# GPIO register map
Vendor: Texas Instruments
Peripheral module from a debugger description file (folder CC27xxx15).
Registers are 32-bit, access per field, reset 0x0 unless marked. A register's access mark holds for its fields unless they carry their own. Offsets are as the file gives them; lines under a group give offsets from that group; [hi:lo] are bit positions; {n}, {i} and the like mark numbered series; 'fields as' and 'values as' point back to an identical list; <NAME> marks a mode.

## GPIO — MCU GPIO - I/F for controlling and reading IO status and IO event status
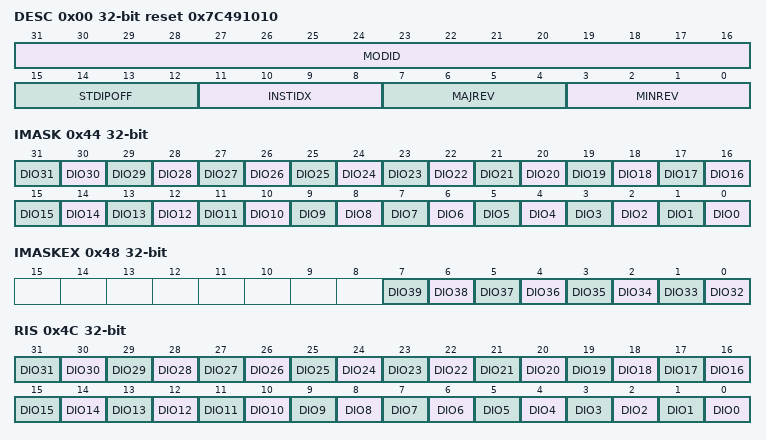
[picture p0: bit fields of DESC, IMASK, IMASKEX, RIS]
0x00 DESC ro reset 0x7C491010 — Description Register. This register provides IP module ID, revision information, instance index and standard MMR registers offset.
  [31:16] MODID — Module identifier used to uniquely identify this IP.
  [15:12] STDIPOFF — Standard IP MMR block offset. Standard IP MMRs are the set from aggregated IRQ registers till DTB. 0: Standard IP MMRs do not exist 0x1-0xF: Standard IP MMRs begin at offset of (64*STDIPOFF from the base IP address)
  [11:8] INSTIDX — IP Instance ID number. If multiple instances of IP exist in the device, this field can identify the instance number (0-15).
  [7:4] MAJREV — Major revision of IP (0-15).
  [3:0] MINREV — Minor revision of IP (0-15).
0x04 DESCEX ro reset 0x27 — Provide IP-specific instance information
  [5:0] NUMDIO — This provides the total number of DIOs supported by GPIO. The number of DIOs supprted is NUMDIO + 1
0x44 IMASK rw — Interrupt mask for DIO pins
  [all] fields
    1=SET (Set Interrrupt Mask); 0=CLR (Clear Interrupt Mask)
  [n] DIO{n} (n=0..31) — Interrupt mask for DIO{n}
0x48 IMASKEX — Interrupt mask for DIO pins
  [all] fields
    1=SET (Set Interrrupt Mask); 0=CLR (Clear Interrupt Mask)
  [n-32] DIO{n} rw (n=32..39) — Interrupt mask for DIO{n}
0x4C RIS ro — Raw interrupt flag for DIO pins
  [all] fields
    1=SET (Interrupt occured); 0=CLR (Interrupt did not occur)
  [n] DIO{n} (n=0..31) — Raw interrupt flag for DIO{n}
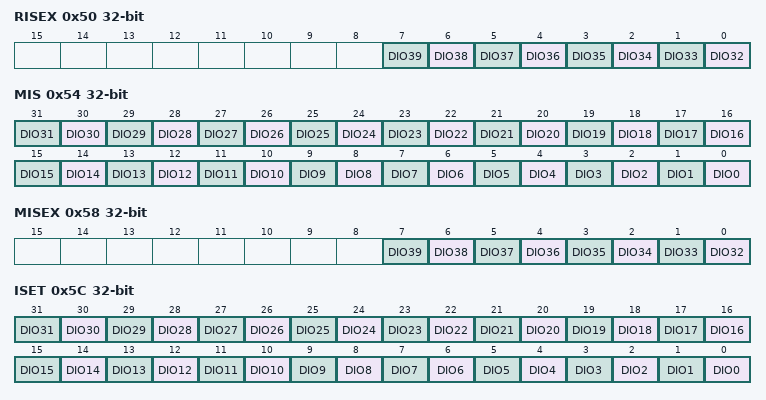
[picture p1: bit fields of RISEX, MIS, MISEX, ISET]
0x50 RISEX ro — Raw interrupt flag for DIO pins
  [all] fields
    1=SET (Interrupt occured); 0=CLR (Interrupt did not occur)
  [n-32] DIO{n} (n=32..39) — Raw interrupt flag for DIO{n}
0x54 MIS ro — Masked interrupt flag for DIO pins
  [all] fields
    1=SET (Interrupt occured); 0=CLR (Interrupt did not occur)
  [n] DIO{n} (n=0..31) — Masked interrupt flag for DIO{n}
0x58 MISEX ro — Masked interrupt flag for DIO pins
  [all] fields
    1=SET (Interrupt occured); 0=CLR (Interrupt did not occur)
  [n-32] DIO{n} (n=32..39) — Masked interrupt flag for DIO{n}
0x5C ISET wo — Set interrupt flag in RIS by writing a one
  [all] fields
    1=SET (Set Interrupt); 0=NOEFF (Writing 0 has no effect)
  [n] DIO{n} (n=0..31) — Set DIO{n} in RIS
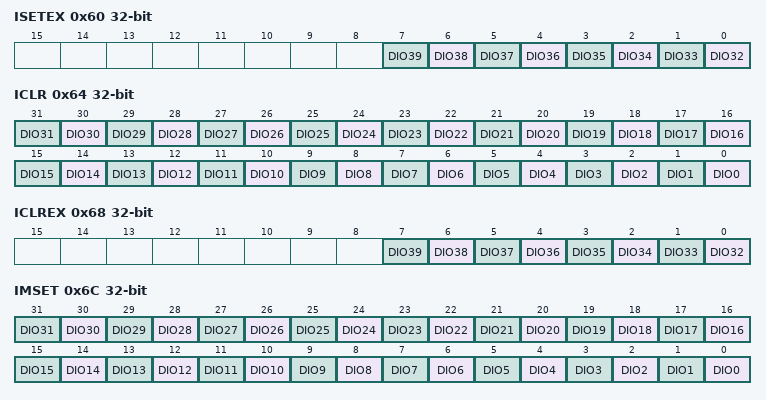
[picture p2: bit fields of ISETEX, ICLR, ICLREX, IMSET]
0x60 ISETEX — Set interrupt flag in RIS by writing a one
  [all] fields
    1=SET (Set Interrupt); 0=NOEFF (Writing 0 has no effect)
  [n-32] DIO{n} wo (n=32..39) — Set DIO{n} in RIS
0x64 ICLR wo — Clear interrupt flag in RIS by writing a one
  [all] fields
    1=CLR (Clear Interrupt); 0=NOEFF (Writing 0 has no effect)
  [n] DIO{n} (n=0..31) — Clears DIO{n} in RIS
0x68 ICLREX — Clear interrupt flag in RIS by writing a one
  [all] fields
    1=CLR (Clear Interrupt); 0=NOEFF (Writing 0 has no effect)
  [n-32] DIO{n} wo (n=32..39) — Clears DIO{n} in RIS
0x6C IMSET wo — Set interrupt mask in IMASK by writing a one
  [all] fields
    1=SET (Set interrupt mask); 0=NOEFF (Writing 0 has no effect)
  [n] DIO{n} (n=0..31) — Sets DIO{n} in IMASK
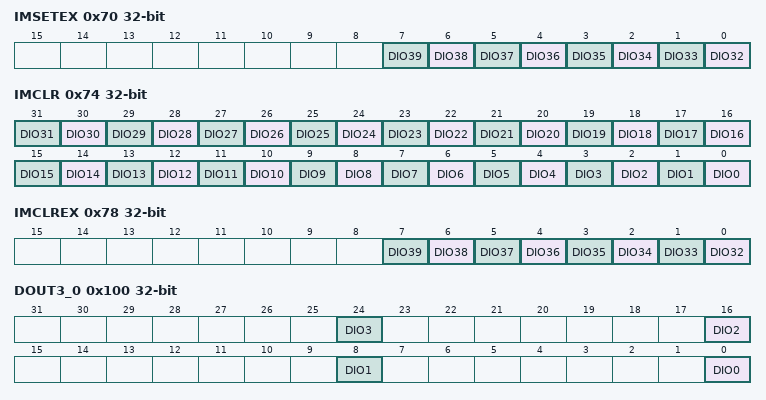
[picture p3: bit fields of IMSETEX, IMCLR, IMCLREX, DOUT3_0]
0x70 IMSETEX — Set interrupt mask in IMASK by writing a one
  [all] fields
    values as the fields of IMSET
  [n-32] DIO{n} wo (n=32..39) — Sets DIO{n} in IMASK
0x74 IMCLR wo — Clear interrupt mask in IMASK by writing a one
  [all] fields
    1=CLR (Clear interrupt mask); 0=NOEFF (Writing 0 has no effect)
  [n] DIO{n} (n=0..31) — Clears DIO{n} in IMASK
0x78 IMCLREX — Clear interrupt mask in IMASK by writing a one
  [all] fields
    values as the fields of IMCLR
  [n-32] DIO{n} wo (n=32..39) — Clears DIO{n} in IMASK
0x100 DOUT3_0 — Alias register for byte access to DOUT31_0[3:0] bits.
  [all] fields
    1=ONE (Output is set to 1); 0=ZERO (Output is set to 0)
  [8n] DIO{n} rw (n=0..3) — Data output for DIO{n}
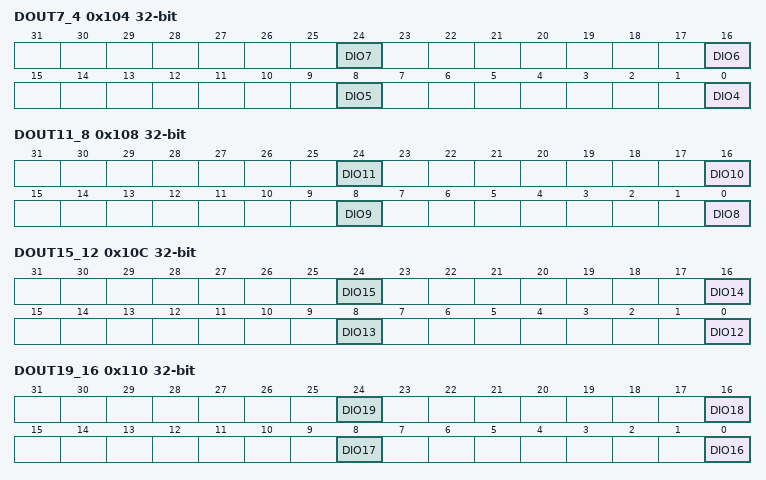
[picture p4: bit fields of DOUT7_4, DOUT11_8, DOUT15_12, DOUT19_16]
0x104 DOUT7_4 — Alias register for byte access to DOUT31_0[7:4] bits
  [all] fields
    1=ONE (Output is set to 1); 0=ZERO (Output is set to 0)
  [8n-32] DIO{n} rw (n=4..7) — Data output for DIO{n}
0x108 DOUT11_8 — Alias register for byte access to DOUT31_0[11:8] bits
  [all] fields
    1=ONE (Output is set to 1); 0=ZERO (Output is set to 0)
  [8n-64] DIO{n} rw (n=8..11) — Data output for DIO{n}
0x10C DOUT15_12 — Alias register for byte access to DOUT31_0[15:12] bits
  [all] fields
    1=ONE (Output is set to 1); 0=ZERO (Output is set to 0)
  [8n-96] DIO{n} rw (n=12..15) — Data output for DIO{n}
0x110 DOUT19_16 — Alias register for byte access to DOUT31_0[19:16] bits
  [all] fields
    1=ONE (Output is set to 1); 0=ZERO (Output is set to 0)
  [8n-128] DIO{n} rw (n=16..19) — Data output for DIO{n}
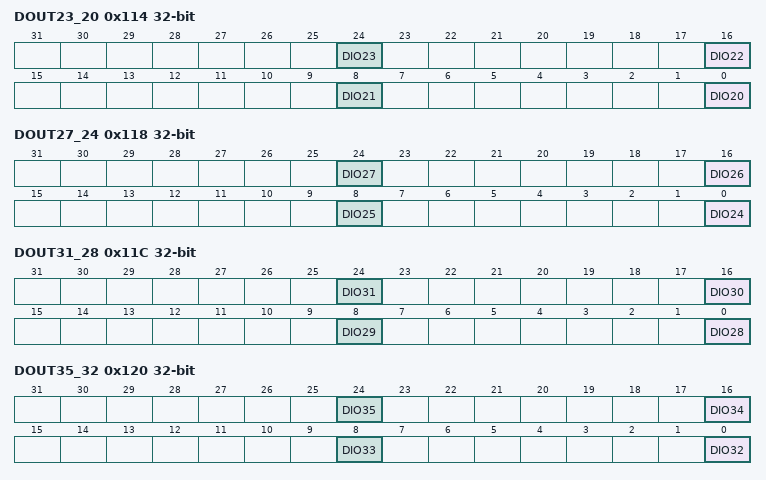
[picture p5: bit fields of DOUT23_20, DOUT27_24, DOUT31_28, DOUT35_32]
0x114 DOUT23_20 — Alias register for byte access to DOUT31_0[23:20] bits
  [all] fields
    1=ONE (Output is set to 1); 0=ZERO (Output is set to 0)
  [8n-160] DIO{n} rw (n=20..23) — Data output for DIO{n}
0x118 DOUT27_24 — Alias register for byte access to DOUT31_0[27:24] bits
  [all] fields
    1=ONE (Output is set to 1); 0=ZERO (Output is set to 0)
  [8n-192] DIO{n} rw (n=24..27) — Data output for DIO{n}
0x11C DOUT31_28 — Alias register for byte access to DOUT31_0[31:28] bits
  [all] fields
    1=ONE (Output is set to 1); 0=ZERO (Output is set to 0)
  [8n-224] DIO{n} rw (n=28..31) — Data output for DIO{n}
0x120 DOUT35_32 — Alias register for byte access to DOUT63_32[35:32] bits
  [all] fields
    1=ONE (Output is set to 1); 0=ZERO (Output is set to 0)
  [8n-256] DIO{n} rw (n=32..35) — Data output for DIO{n}
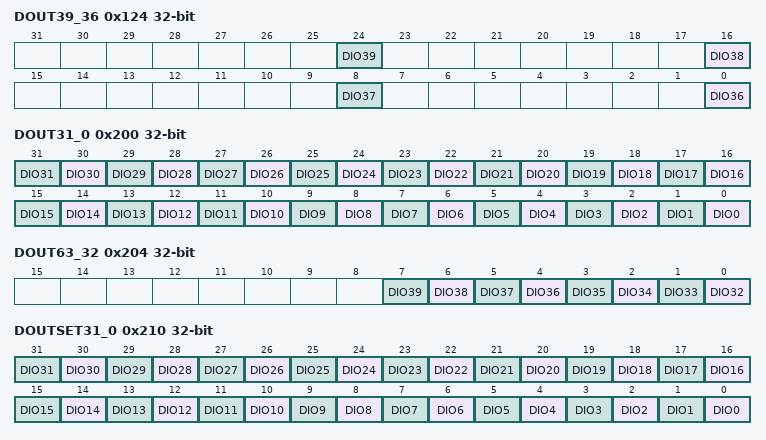
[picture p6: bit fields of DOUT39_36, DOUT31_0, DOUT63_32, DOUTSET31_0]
0x124 DOUT39_36 — Alias register for byte access to DOUT63_32[39:36] bits
  [all] fields
    1=ONE (Output is set to 1); 0=ZERO (Output is set to 0)
  [8n-288] DIO{n} rw (n=36..39) — Data output for DIO{n}
0x200 DOUT31_0 rw — Data Output for DIO 31 to 0 pins.
  [all] fields
    1=ONE (Output is set to 1); 0=ZERO (Output is set to 0)
  [n] DIO{n} (n=0..31) — Data output for DIO{n}
0x204 DOUT63_32 — Data Output for DIO 63 to 32 pins.
  [all] fields
    1=ONE (Output is set to 1); 0=ZERO (Output is set to 0)
  [n-32] DIO{n} rw (n=32..39) — Data output for DIO{n}
0x210 DOUTSET31_0 wo — Alias regiser to set the corresponding bits of DOUT31_0 register.
  [all] fields
    1=SET; 0=NOEFF (No effect)
  [n] DIO{n} (n=0..31) — Set bit DOUT31_0.DIO{n}
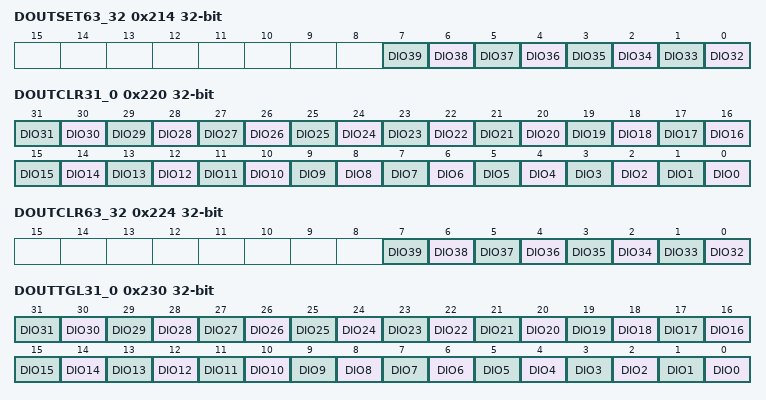
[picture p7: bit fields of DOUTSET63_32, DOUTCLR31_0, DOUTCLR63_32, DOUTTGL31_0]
0x214 DOUTSET63_32 — Alias regiser to set the corresponding bits of DOUT63_32 register.
  [all] fields
    1=SET; 0=NOEFF (No effect)
  [n-32] DIO{n} wo (n=32..39) — Set bit DOUT63_32.DIO{n}
0x220 DOUTCLR31_0 wo — Alias regiser to clear the corresponding bits of DOUT31_0 register.
  [all] fields
    1=CLR (Clear); 0=NOEFF (No effect)
  [n] DIO{n} (n=0..31) — Clear bit DOUT31_0.DIO{n}
0x224 DOUTCLR63_32 — Alias regiser to clear the corresponding bits of DOUT63_32 register.
  [all] fields
    1=CLR (Clear); 0=NOEFF (No effect)
  [n-32] DIO{n} wo (n=32..39) — Clear bit DOUT63_32.DIO{n}
0x230 DOUTTGL31_0 wo — Alias regiser to toggle the corresponding bits of DOUT31_0 register.
  [all] fields
    1=TOGGLE; 0=NOEFF (No effect)
  [n] DIO{n} (n=0..31) — Toggles bit DOUT31_0.DIO{n}
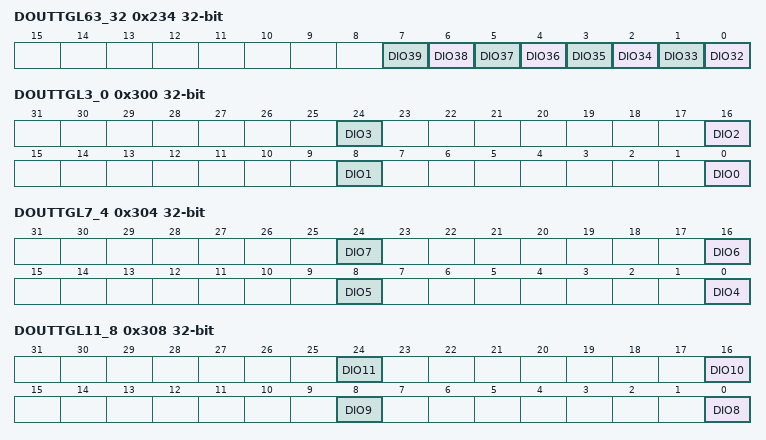
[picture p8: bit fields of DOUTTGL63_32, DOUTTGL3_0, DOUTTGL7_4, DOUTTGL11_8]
0x234 DOUTTGL63_32 — Alias regiser to toggle the corresponding bits of DOUT63_32 register.
  [all] fields
    1=TOGGLE; 0=NOEFF (No effect)
  [n-32] DIO{n} wo (n=32..39) — Toggles bit DOUT63_32.DIO{n}
0x300 DOUTTGL3_0 — Alias regiser to toggle the corresponding bits of DOUT31_0[3:0] register.
  [all] fields
    1=TOGGLE; 0=NOEFF (No effect)
  [8n] DIO{n} wo (n=0..3) — Toggles bit DOUT31_0.DIO{n}
0x304 DOUTTGL7_4 — Alias regiser to toggle the corresponding bits of DOUT31_0[7:4] register.
  [all] fields
    1=TOGGLE; 0=NOEFF (No effect)
  [8n-32] DIO{n} wo (n=4..7) — Toggles bit DOUT31_0.DIO{n}
0x308 DOUTTGL11_8 — Alias regiser to toggle the corresponding bits of DOUT31_0[11:8] register.
  [all] fields
    1=TOGGLE; 0=NOEFF (No effect)
  [8n-64] DIO{n} wo (n=8..11) — Toggles bit DOUT31_0.DIO{n}
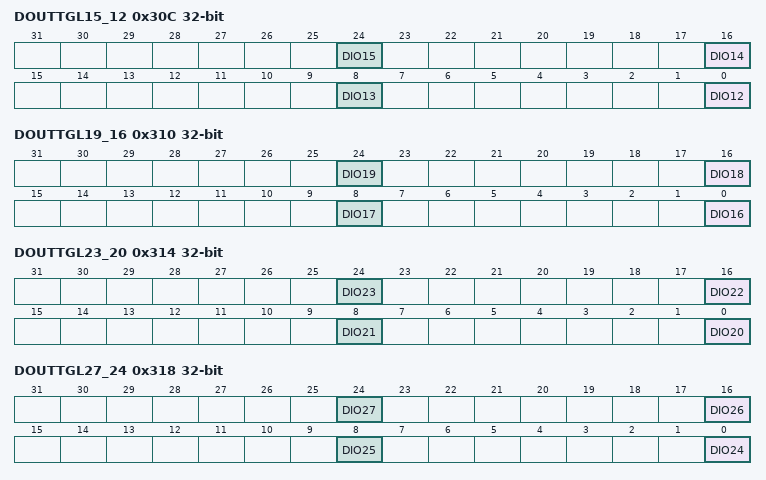
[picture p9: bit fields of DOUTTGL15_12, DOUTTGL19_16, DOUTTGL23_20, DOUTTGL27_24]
0x30C DOUTTGL15_12 — Alias regiser to toggle the corresponding bits of DOUT31_0[15:12] register.
  [all] fields
    1=TOGGLE; 0=NOEFF (No effect)
  [8n-96] DIO{n} wo (n=12..15) — Toggles bit DOUT31_0.DIO{n}
0x310 DOUTTGL19_16 — Alias regiser to toggle the corresponding bits of DOUT31_0[19:16] register.
  [all] fields
    1=TOGGLE; 0=NOEFF (No effect)
  [8n-128] DIO{n} wo (n=16..19) — Toggles bit DOUT31_0.DIO{n}
0x314 DOUTTGL23_20 — Alias regiser to toggle the corresponding bits of DOUT31_0[23:20] register.
  [all] fields
    1=TOGGLE; 0=NOEFF (No effect)
  [8n-160] DIO{n} wo (n=20..23) — Toggles bit DOUT31_0.DIO{n}
0x318 DOUTTGL27_24 — Alias regiser to toggle the corresponding bits of DOUT31_0[27:24] register.
  [all] fields
    1=TOGGLE; 0=NOEFF (No effect)
  [8n-192] DIO{n} wo (n=24..27) — Toggles bit DOUT31_0.DIO{n}
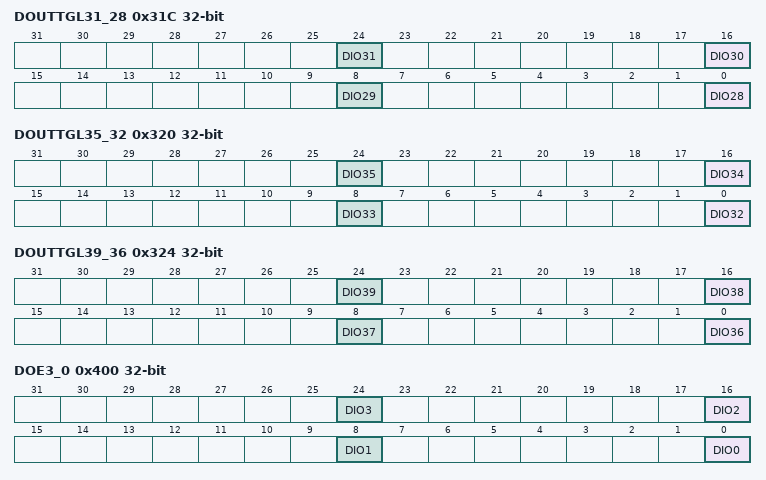
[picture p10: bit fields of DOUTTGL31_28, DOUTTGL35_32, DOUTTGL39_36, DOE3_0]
0x31C DOUTTGL31_28 — Alias regiser to toggle the corresponding bits of DOUT31_0[31:28] register.
  [all] fields
    1=TOGGLE; 0=NOEFF (No effect)
  [8n-224] DIO{n} wo (n=28..31) — Toggles bit DOUT31_0.DIO{n}
0x320 DOUTTGL35_32 — Alias regiser to toggle the corresponding bits of DOUT63_32[35:32] register.
  [all] fields
    1=TOGGLE; 0=NOEFF (No effect)
  [8n-256] DIO{n} wo (n=32..35) — Toggles bit DOUT63_32.DIO{n}
0x324 DOUTTGL39_36 — Alias regiser to toggle the corresponding bits of DOUT63_32[39:36] register.
  [all] fields
    1=TOGGLE; 0=NOEFF (No effect)
  [8n-288] DIO{n} wo (n=36..39) — Toggles bit DOUT63_32.DIO{n}
0x400 DOE3_0 — Alias register for byte access to DOE31_0[3:0] bits.
  [all] fields
    1=EN (Output enabled); 0=DIS (Output disabled)
  [8n] DIO{n} rw (n=0..3) — Data output enable for DIO{n}
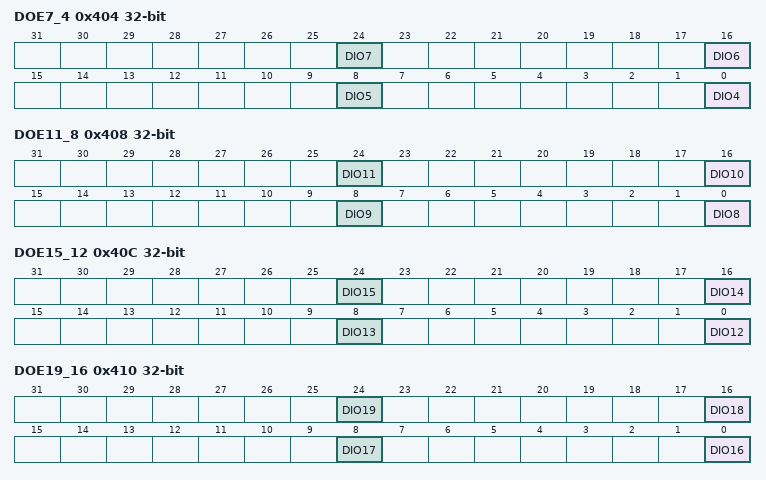
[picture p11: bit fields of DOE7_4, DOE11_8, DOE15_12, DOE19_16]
0x404 DOE7_4 — Alias register for byte access to DOE31_0[7:4] bits.
  [all] fields
    1=EN (Output enabled); 0=DIS (Output disabled)
  [8n-32] DIO{n} rw (n=4..7) — Data output enable for DIO{n}
0x408 DOE11_8 — Alias register for byte access to DOE31_0[11:8] bits.
  [all] fields
    1=EN (Output enabled); 0=DIS (Output disabled)
  [8n-64] DIO{n} rw (n=8..11) — Data output enable for DIO{n}
0x40C DOE15_12 — Alias register for byte access to DOE31_0[15:12] bits.
  [all] fields
    1=EN (Output enabled); 0=DIS (Output disabled)
  [8n-96] DIO{n} rw (n=12..15) — Data output enable for DIO{n}
0x410 DOE19_16 — Alias register for byte access to DOE31_0[19:16] bits.
  [all] fields
    1=EN (Output enabled); 0=DIS (Output disabled)
  [8n-128] DIO{n} rw (n=16..19) — Data output enable for DIO{n}
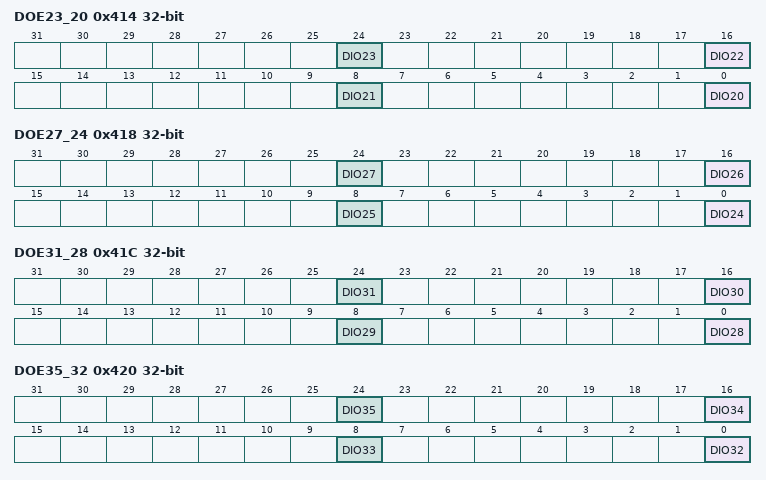
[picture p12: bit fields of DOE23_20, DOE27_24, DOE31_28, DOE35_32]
0x414 DOE23_20 — Alias register for byte access to DOE31_0[23:20] bits.
  [all] fields
    1=EN (Output enabled); 0=DIS (Output disabled)
  [8n-160] DIO{n} rw (n=20..23) — Data output enable for DIO{n}
0x418 DOE27_24 — Alias register for byte access to DOE31_0[24:27] bits.
  [all] fields
    1=EN (Output enabled); 0=DIS (Output disabled)
  [8n-192] DIO{n} rw (n=24..27) — Data output enable for DIO{n}
0x41C DOE31_28 — Alias register for byte access to DOE31_0[31:28] bits.
  [all] fields
    1=EN (Output enabled); 0=DIS (Output disabled)
  [8n-224] DIO{n} rw (n=28..31) — Data output enable for DIO{n}
0x420 DOE35_32 — Alias register for byte access to DOE63_32[35:32] bits.
  [all] fields
    1=EN (Output enabled); 0=DIS (Output disabled)
  [8n-256] DIO{n} rw (n=32..35) — Data output enable for DIO{n}
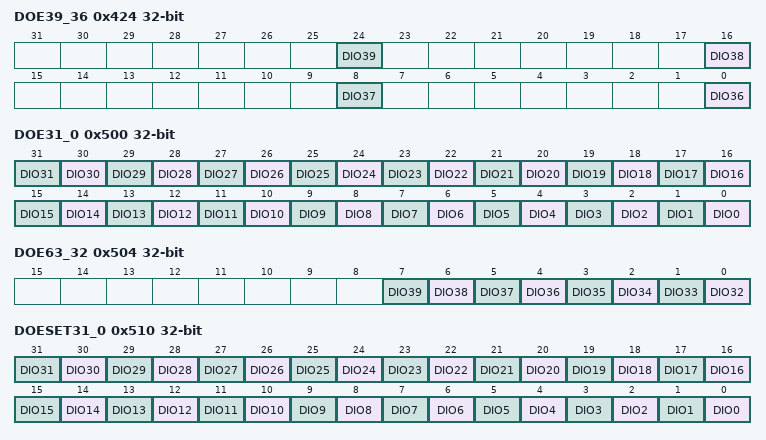
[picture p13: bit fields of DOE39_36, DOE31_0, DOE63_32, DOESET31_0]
0x424 DOE39_36 — Alias register for byte access to DOE63_32[39:36] bits.
  [all] fields
    1=EN (Output enabled); 0=DIS (Output disabled)
  [8n-288] DIO{n} rw (n=36..39) — Data output enable for DIO{n}
0x500 DOE31_0 rw — Data output enable for DIO 31 to 0 pins.
  [all] fields
    1=EN (Output enabled); 0=DIS (Output disabled)
  [n] DIO{n} (n=0..31) — Data output enable for DIO{n}
0x504 DOE63_32 — Data output enable for DIO 63 to 32 pins.
  [all] fields
    1=EN (Output enabled); 0=DIS (Output disabled)
  [n-32] DIO{n} rw (n=32..39) — Data output enable for DIO{n}
0x510 DOESET31_0 wo — Alias regiser to set the corresponding bits of DOE31_0 register.
  [all] fields
    1=SET; 0=NOEFF (No effect)
  [n] DIO{n} (n=0..31) — Sets bit DOE31_0.DIO{n}
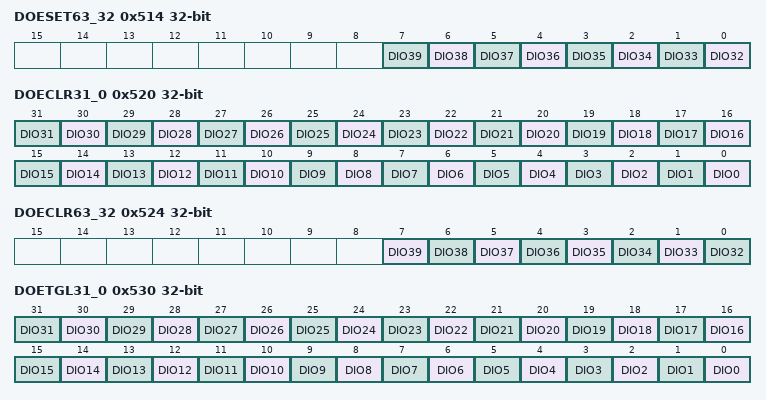
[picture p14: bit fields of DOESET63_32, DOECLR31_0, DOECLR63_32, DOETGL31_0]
0x514 DOESET63_32 — Alias regiser to set the corresponding bits of DOE63_32 register.
  [all] fields
    1=SET; 0=NOEFF (No effect)
  [n-32] DIO{n} wo (n=32..39) — Sets bit DOE63_32.DIO{n}
0x520 DOECLR31_0 wo — Alias regiser to clear the corresponding bits of DOE31_0 register.
  [all] fields
    1=CLR (Clear); 0=NOEFF (No effect)
  [n] DIO{n} (n=0..31) — Clears bit DOE31_0.DIO{n}
0x524 DOECLR63_32 — Alias regiser to clear the corresponding bits of DOE63_32 register.
  [all] fields
    1=CLR (Clear); 0=NOEFF (No effect)
  [7] DIO39 wo — Clears bit DOE63_32DIO39
  [n-32] DIO{n} wo (n=32..38) — Clears bit DOE63_32.DIO{n}
0x530 DOETGL31_0 wo — Alias regiser to toggle the corresponding bits of DOE31_0 register.
  [all] fields
    1=TOGGLE; 0=NOEFF (No effect)
  [n] DIO{n} (n=0..31) — Toggles bit DOE31_0.DIO{n}
0x534 DOETGL63_32 — Alias regiser to toggle the corresponding bits of DOE63_32 register.
  [all] fields
    1=TOGGLE; 0=NOEFF (No effect)
  [n-32] DIO{n} wo (n=34..39) — Toggles bit DOE63_32.DIO{n}
  [1] DIO33 wo — Toggles bit DOE363_32.DIO33
  [0] DIO32 wo — Toggles bit DOE63_32.DIO32
0x600 DIN3_0 ro — Alias register for byte access to DIN31_0[3:0] bits.
  [all] fields
    1=ONE (Input value is 1); 0=ZERO (Input value is 0)
  [8n] DIO{n} (n=0..3) — Data input from DIO{n}
0x604 DIN7_4 ro — Alias register for byte access to DIN31_0[7:4] bits.
  [all] fields
    1=ONE (Input value is 1); 0=ZERO (Input value is 0)
  [8n-32] DIO{n} (n=4..7) — Data input from DIO{n}
0x608 DIN11_8 ro — Alias register for byte access to DIN31_0[11:8] bits.
  [all] fields
    1=ONE (Input value is 1); 0=ZERO (Input value is 0)
  [8n-64] DIO{n} (n=8..11) — Data input from DIO{n}
0x60C DIN15_12 ro — Alias register for byte access to DIN31_0[15:12] bits.
  [all] fields
    1=ONE (Input value is 1); 0=ZERO (Input value is 0)
  [8n-96] DIO{n} (n=12..15) — Data input from DIO{n}
0x610 DIN19_16 ro — Alias register for byte access to DIN31_0[19:16] bits.
  [all] fields
    1=ONE (Input value is 1); 0=ZERO (Input value is 0)
  [8n-128] DIO{n} (n=16..19) — Data input from DIO{n}
0x614 DIN23_20 ro — Alias register for byte access to DIN31_0[23:20] bits.
  [all] fields
    1=ONE (Input value is 1); 0=ZERO (Input value is 0)
  [8n-160] DIO{n} (n=20..23) — Data input from DIO{n}
0x618 DIN27_24 ro — Alias register for byte access to DIN31_0[24:27] bits.
  [all] fields
    1=ONE (Input value is 1); 0=ZERO (Input value is 0)
  [8n-192] DIO{n} (n=24..27) — Data input from DIO{n}
0x61C DIN31_28 ro — Alias register for byte access to DIN31_0[31:28] bits.
  [all] fields
    1=ONE (Input value is 1); 0=ZERO (Input value is 0)
  [8n-224] DIO{n} (n=28..31) — Data input from DIO{n}
0x620 DIN35_32 ro — Alias register for byte access to DIN63_32[35:32] bits.
  [all] fields
    1=ONE (Input value is 1); 0=ZERO (Input value is 0)
  [8n-256] DIO{n} (n=32..35) — Data input from DIO{n}
0x624 DIN39_36 ro — Alias register for byte access to DIN63_32[39:36] bits.
  [all] fields
    1=ONE (Input value is 1); 0=ZERO (Input value is 0)
  [8n-288] DIO{n} (n=36..39) — Data input from DIO{n}
0x700 DIN31_0 ro — Data input from DIO 31 to 0 pins.
  [all] fields
    1=ONE (Input value is 1); 0=ZERO (Input value is 0)
  [n] DIO{n} (n=0..31) — Data input from DIO{n}
0x704 DIN63_32 ro — Data input from DIO 63 to 32 pins.
  [all] fields
    1=ONE (Input value is 1); 0=ZERO (Input value is 0)
  [n-32] DIO{n} (n=32..39) — Data input from DIO{n}
0x800 EVTCFG — Event configuration 0. This register is used to select DIO for GPIO to publish event on SVT event fabric. It also contains enable bit that is used to mask the event.
  [8] EVTEN rw — Enables GPIO to publish edge qualified selected DIO event on SVT event fabric. Design note: The edge detector flop is cleared automatically for the selected DIO once the event is published.
    1=EN (Enable); 0=DIS (Disable)
  [5:0] DIOSEL rw — This is used to select DIO for event generation. For example, DIOSEL = 0x0 selects DIO0 and DIOSEL = 0x8 selects DIO8.
    63=MAXIMUM (Maximum value); 0=MINIMUM (Minimum value)
0x810 EVTCFG1 — Event configuration 1. This register is used to select DIO for GPIO to publish event on SVT event fabric. It also contains enable bit that is used to mask the event.
  fields as EVTCFG
